# SF32LB55x register map
File version: 1.0
CPU: CM33 r0p1, little endian, MPU, FPU, 3 interrupt priority bits
Registers are 32-bit, read-write, reset 0x0 unless marked. A register's access mark holds for its fields unless they carry their own. Offsets are from the block's base; [hi:lo] are bit positions; {n}, {i} and the like mark numbered series; 'fields as' and 'values as' point back to an identical list.

## LPSYS_RCC
Base 0x40040000
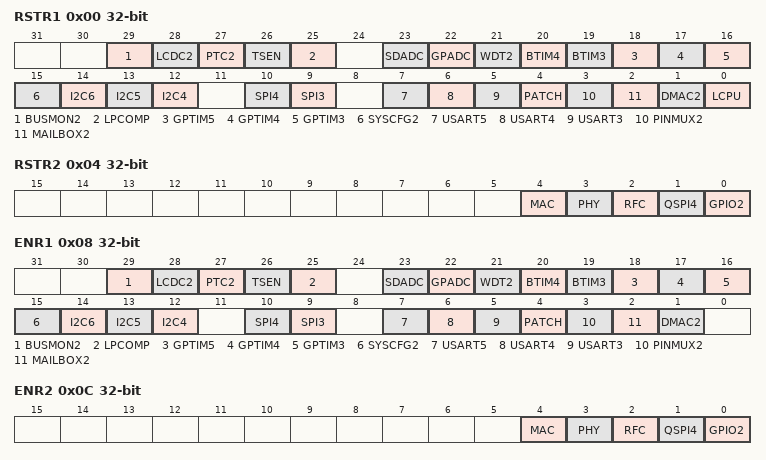
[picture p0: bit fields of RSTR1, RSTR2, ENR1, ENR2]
0x00 RSTR1 — Reset Register
  [29] BUSMON2 — 0 - no reset; 1 - reset
  [28] LCDC2 — 0 - no reset; 1 - reset
  [27] PTC2 — 0 - no reset; 1 - reset
  [26] TSEN — 0 - no reset; 1 - reset
  [25] LPCOMP — 0 - no reset; 1 - reset
  [23] SDADC — 0 - no reset; 1 - reset
  [22] GPADC — 0 - no reset; 1 - reset
  [21] WDT2 — 0 - no reset; 1 - reset
  [20] BTIM4 — 0 - no reset; 1 - reset
  [19] BTIM3 — 0 - no reset; 1 - reset
  [18] GPTIM5 — 0 - no reset; 1 - reset
  [17] GPTIM4 — 0 - no reset; 1 - reset
  [16] GPTIM3 — 0 - no reset; 1 - reset
  [15] SYSCFG2 — 0 - no reset; 1 - reset
  [14] I2C6 — 0 - no reset; 1 - reset
  [13] I2C5 — 0 - no reset; 1 - reset
  [12] I2C4 — 0 - no reset; 1 - reset
  [10] SPI4 — 0 - no reset; 1 - reset
  [9] SPI3 — 0 - no reset; 1 - reset
  [7] USART5 — 0 - no reset; 1 - reset
  [6] USART4 — 0 - no reset; 1 - reset
  [5] USART3 — 0 - no reset; 1 - reset
  [4] PATCH — 0 - no reset; 1 - reset
  [3] PINMUX2 — 0 - no reset; 1 - reset
  [2] MAILBOX2 — 0 - no reset; 1 - reset
  [1] DMAC2 — 0 - no reset; 1 - reset
  [0] LCPU — 0 - no reset; 1 - reset
0x04 RSTR2 — Reset Register2
  [4] MAC — 0 - no reset; 1 - reset
  [3] PHY — 0 - no reset; 1 - reset
  [2] RFC — 0 - no reset; 1 - reset
  [1] QSPI4 — 0 - no reset; 1 - reset
  [0] GPIO2 — 0 - no reset; 1 - reset
0x08 ENR1 — Enable Register
  [29] BUSMON2 — 0 - disabled; 1 - enabled
  [28] LCDC2 — 0 - disabled; 1 - enabled
  [27] PTC2 — 0 - disabled; 1 - enabled
  [26] TSEN — 0 - disabled; 1 - enabled
  [25] LPCOMP — 0 - disabled; 1 - enabled
  [23] SDADC — 0 - disabled; 1 - enabled
  [22] GPADC — 0 - disabled; 1 - enabled
  [21] WDT2 — 0 - disabled; 1 - enabled
  [20] BTIM4 — 0 - disabled; 1 - enabled
  [19] BTIM3 — 0 - disabled; 1 - enabled
  [18] GPTIM5 — 0 - disabled; 1 - enabled
  [17] GPTIM4 — 0 - disabled; 1 - enabled
  [16] GPTIM3 — 0 - disabled; 1 - enabled
  [15] SYSCFG2 — 0 - disabled; 1 - enabled
  [14] I2C6 — 0 - disabled; 1 - enabled
  [13] I2C5 — 0 - disabled; 1 - enabled
  [12] I2C4 — 0 - disabled; 1 - enabled
  [10] SPI4 — 0 - disabled; 1 - enabled
  [9] SPI3 — 0 - disabled; 1 - enabled
  [7] USART5 — 0 - disabled; 1 - enabled
  [6] USART4 — 0 - disabled; 1 - enabled
  [5] USART3 — 0 - disabled; 1 - enabled
  [4] PATCH — 0 - disabled; 1 - enabled
  [3] PINMUX2 — 0 - disabled; 1 - enabled
  [2] MAILBOX2 — 0 - disabled; 1 - enabled
  [1] DMAC2 — 0 - disabled; 1 - enabled
0x0C ENR2 — Enable Register2
  [4] MAC — 0 - disabled; 1 - enabled
  [3] PHY — 0 - disabled; 1 - enabled
  [2] RFC — 0 - disabled; 1 - enabled
  [1] QSPI4 — 0 - disabled; 1 - enabled
  [0] GPIO2 — 0 - disabled; 1 - enabled
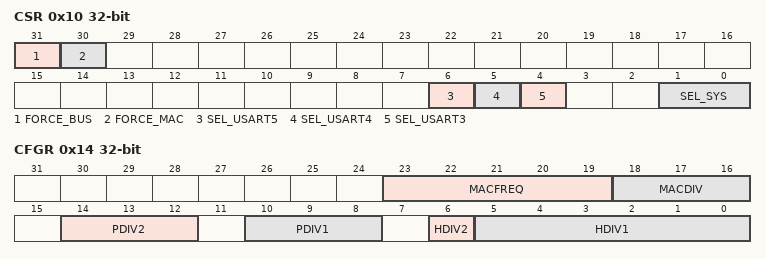
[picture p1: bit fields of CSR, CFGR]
0x10 CSR — Clock Select Register
  [31] FORCE_BUS — for debug only
  [30] FORCE_MAC — for debug only
  [6] SEL_USART5 — 0 - hrc48; 1 - hxt48
  [5] SEL_USART4 — 0 - hrc48; 1 - hxt48
  [4] SEL_USART3 — 0 - hrc48; 1 - hxt48
  [1:0] SEL_SYS — select clk_sys source 0 - hrc48; 1 - hxt48; 2 - CLK_LP; 3 - RSVD
0x14 CFGR — Clock Configuration Register
  [23:19] MACFREQ — clock frequency of MAC clock
  [18:16] MACDIV — MAC clock divider MAC clock = hclk / MACDIV
  [14:12] PDIV2 — pclk2 = hclk / (2^PDIV2), by default divided by 8
  [10:8] PDIV1 — pclk1 = hclk / (2^PDIV1), by default divided by 2
  [6] HDIV2 — should set to 0 if hclk frequency no higher than 24MHz should set to 1 if hclk frequency higher than 24MHz
  [5:0] HDIV1 — hclk = clk_sys / HDIV1 if HDIV1=0, hclk = clk_sys

## LPSYS_PINMUX
Base 0x40043000
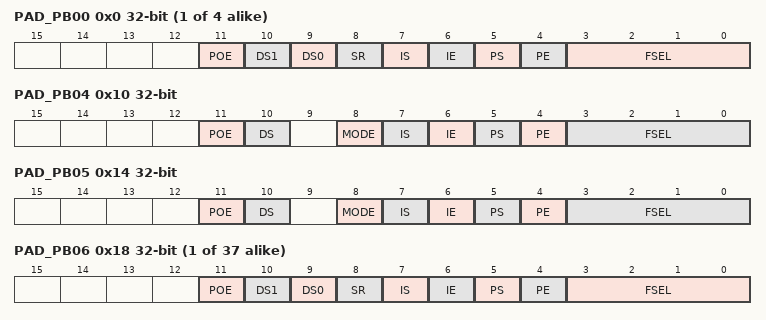
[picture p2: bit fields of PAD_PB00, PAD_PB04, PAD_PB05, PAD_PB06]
{0x0+4i} PAD_PB{i:02} (i=0..3)
  [11] POE — Parametric output enable. Logic LOW forces PO HIGH.
  [10] DS1 — Drive select 1. Used to select output drive strength.
  [9] DS0 — Drive select 0. Used to select output drive strength.
  [8] SR — Slew rate. Logic HIGH selects slow slew rate, logic LOW selects fast slew rate.
  [7] IS — Input select. Logic LOW selects CMOS input, and logic HIGH selects Schmitt input.
  [6] IE — Input enable. Logic HIGH enables the input buffer.
  [5] PS — Pull select. Logic HIGH selects pull-up, logic LOW selected pull-down.
  [4] PE — Pull enable. Logic HIGH enables weak pull device.
  [3:0] FSEL — Function Select
0x10 PAD_PB04
  [11] POE — Parametric output enable. Logic LOW forces PO HIGH.
  [10] DS — Drive select. Logic LOW selects 4mA drive, logic HIGH selects 20mA drive.
  [8] MODE — Mode select. Logic LOW enables GPIO mode, logic HIGH enables I2C mode.
  [7] IS — Input select. Logic LOW selects CMOS input, and logic HIGH selects Schmitt input.
  [6] IE — Input enable. Logic HIGH enables the input buffer.
  [5] PS — Pull select. Logic HIGH selects pull-up, logic LOW selected pull-down.
  [4] PE — Pull enable. Logic HIGH enables weak pull device.
  [3:0] FSEL — Function Select
0x14 PAD_PB05
  fields as PAD_PB04
{0x0+4i} PAD_PB{i:02} (i=6..42)
  fields as PAD_PB00
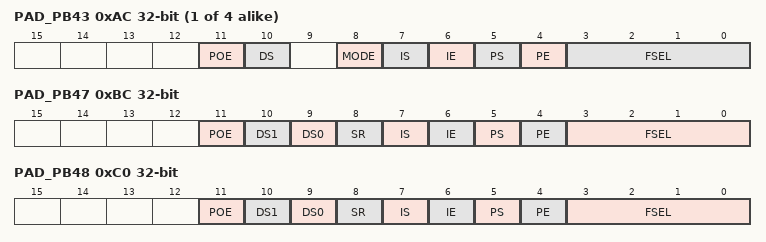
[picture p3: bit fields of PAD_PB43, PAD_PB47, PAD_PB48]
{0x0+4i} PAD_PB{i} (i=43..46)
  fields as PAD_PB04
0xBC PAD_PB47
  fields as PAD_PB00
0xC0 PAD_PB48
  fields as PAD_PB00
